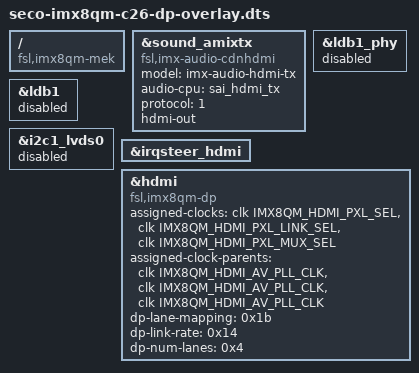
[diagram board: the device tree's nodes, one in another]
/*
 * Copyright 2017-2018 NXP
 *
 * This program is free software; you can redistribute it and/or
 * modify it under the terms of the GNU General Public License
 * as published by the Free Software Foundation; either version 2
 * of the License, or (at your option) any later version.
 *
 * This program is distributed in the hope that it will be useful,
 * but WITHOUT ANY WARRANTY; without even the implied warranty of
 * MERCHANTABILITY or FITNESS FOR A PARTICULAR PURPOSE.  See the
 * GNU General Public License for more details.
 */
/*
 * Display Port only dts, disable ldb display.
 */

/dts-v1/;
/plugin/;

#include <dt-bindings/clock/imx8qm-clock.h>

/ {
        compatible = "fsl,imx8qm-mek","fsl,seco-imx8qm-c26", "fsl,imx8qm";

/*  __________________________________________________________________________
 * |                                                                          |
 * |                               DP OVERLAY                                 |
 * |__________________________________________________________________________|
 */


	fragment@0 {
                target = <&sound_amixtx>;
                __overlay__ {
				compatible = "fsl,imx-audio-cdnhdmi";
				model = "imx-audio-hdmi-tx";
				audio-cpu = <&sai_hdmi_tx>;
				protocol = <1>;
				hdmi-out;
        		};
        };

	fragment@1 {
                target = <&ldb1_phy>;
                __overlay__ {
                        status = "disabled"; 
                };
        };

	fragment@2 {
                target = <&ldb1>;
                __overlay__ {
                        status = "disabled"; 
                };
        };

	fragment@3 {
                target = <&i2c1_lvds0>;
                __overlay__ {
                        status = "disabled"; 
                };
        };

	fragment@4 {
                target = <&irqsteer_hdmi>;
                __overlay__ {
                        status = "okay"; 
                };
        };

	fragment@5 {
                target = <&hdmi>;
                __overlay__ {
		        compatible = "fsl,imx8qm-dp";
			assigned-clocks = <&clk IMX8QM_HDMI_PXL_SEL>,
							<&clk IMX8QM_HDMI_PXL_LINK_SEL>,
							<&clk IMX8QM_HDMI_PXL_MUX_SEL>;
			assigned-clock-parents = <&clk IMX8QM_HDMI_AV_PLL_CLK>,
							<&clk IMX8QM_HDMI_AV_PLL_CLK>,
							<&clk IMX8QM_HDMI_AV_PLL_CLK>;

			dp-lane-mapping = <0x1b>;
			dp-link-rate = <0x14>;
			dp-num-lanes = <0x4>;

			status = "okay";

                };
        };

};
